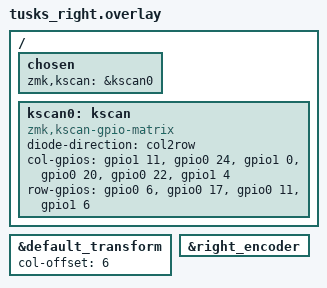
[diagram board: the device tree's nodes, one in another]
#include "tusks.dtsi"
#include "tusks-layouts.dtsi"
#include <dt-bindings/zmk/input_transform.h>

&default_transform {
	col-offset = <6>;
};
&right_encoder {
    status = "okay";
};

/ {
	chosen {
		zmk,kscan = &kscan0;
	};

	kscan0: kscan {
		compatible = "zmk,kscan-gpio-matrix";
		diode-direction = "col2row";
		col-gpios =
            <&gpio1 11 GPIO_ACTIVE_HIGH>,
            <&gpio0 24 GPIO_ACTIVE_HIGH>,
            <&gpio1 0 GPIO_ACTIVE_HIGH>,
            <&gpio0 20 GPIO_ACTIVE_HIGH>,
            <&gpio0 22 GPIO_ACTIVE_HIGH>,
            <&gpio1 4 GPIO_ACTIVE_HIGH>
     ;
		row-gpios =
		    <&gpio0 6 (GPIO_ACTIVE_HIGH | GPIO_PULL_DOWN)>,
		    <&gpio0 17 (GPIO_ACTIVE_HIGH | GPIO_PULL_DOWN)>,
		    <&gpio0 11 (GPIO_ACTIVE_HIGH | GPIO_PULL_DOWN)>,
		    <&gpio1 6 (GPIO_ACTIVE_HIGH | GPIO_PULL_DOWN)>
		    wakeup-source;
		;

	};
};
